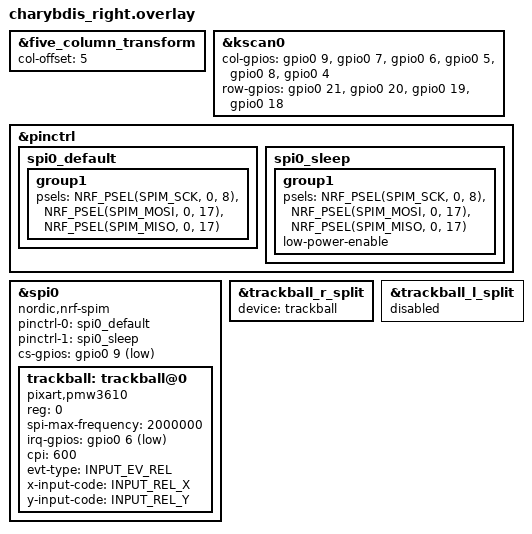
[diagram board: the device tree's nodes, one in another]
#include "charybdis.dtsi"
#include "charybdis_3610.dtsi"
#include "charybdis_zplit.dtsi"
#include <dt-bindings/zmk/input_transform.h>

&five_column_transform {
	col-offset = <5>;
};

&kscan0 {
	col-gpios
		= <&gpio0 9 GPIO_ACTIVE_HIGH>
		, <&gpio0 7 GPIO_ACTIVE_HIGH>
		, <&gpio0 6 GPIO_ACTIVE_HIGH>
		, <&gpio0 5 GPIO_ACTIVE_HIGH>
		, <&gpio0 8 GPIO_ACTIVE_HIGH>
		, <&gpio0 4 GPIO_ACTIVE_HIGH>
		;

	row-gpios
		= <&gpio0 21 (GPIO_ACTIVE_HIGH | GPIO_PULL_DOWN)>
		, <&gpio0 20 (GPIO_ACTIVE_HIGH | GPIO_PULL_DOWN)>
		, <&gpio0 19 (GPIO_ACTIVE_HIGH | GPIO_PULL_DOWN)>
		, <&gpio0 18 (GPIO_ACTIVE_HIGH | GPIO_PULL_DOWN)>
		;
};

&pinctrl {
    spi0_default: spi0_default {
        group1 {
            psels = <NRF_PSEL(SPIM_SCK, 0, 8)>,
                <NRF_PSEL(SPIM_MOSI, 0, 17)>,
                <NRF_PSEL(SPIM_MISO, 0, 17)>;
        };
    };

    spi0_sleep: spi0_sleep {
        group1 {
            psels = <NRF_PSEL(SPIM_SCK, 0, 8)>,
                <NRF_PSEL(SPIM_MOSI, 0, 17)>,
                <NRF_PSEL(SPIM_MISO, 0, 17)>;
            low-power-enable;
        };
    };
};

&spi0 {
    compatible = "nordic,nrf-spim";
    status = "okay";
    pinctrl-0 = <&spi0_default>;
    pinctrl-1 = <&spi0_sleep>;
    pinctrl-names = "default", "sleep";
    cs-gpios = <&gpio0 9 GPIO_ACTIVE_LOW>;

    trackball: trackball@0 {
        compatible = "pixart,pmw3610";
        status = "okay";
        reg = <0>;
        spi-max-frequency = <2000000>;
        irq-gpios = <&gpio0 6 (GPIO_ACTIVE_LOW | GPIO_PULL_UP)>;
        cpi = <600>;
        evt-type = <INPUT_EV_REL>;
        x-input-code = <INPUT_REL_X>;
        y-input-code = <INPUT_REL_Y>;
    };
};

&trackball_r_split {
	device = <&trackball>;
};

&trackball_l_split {
	status = "disabled";
};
